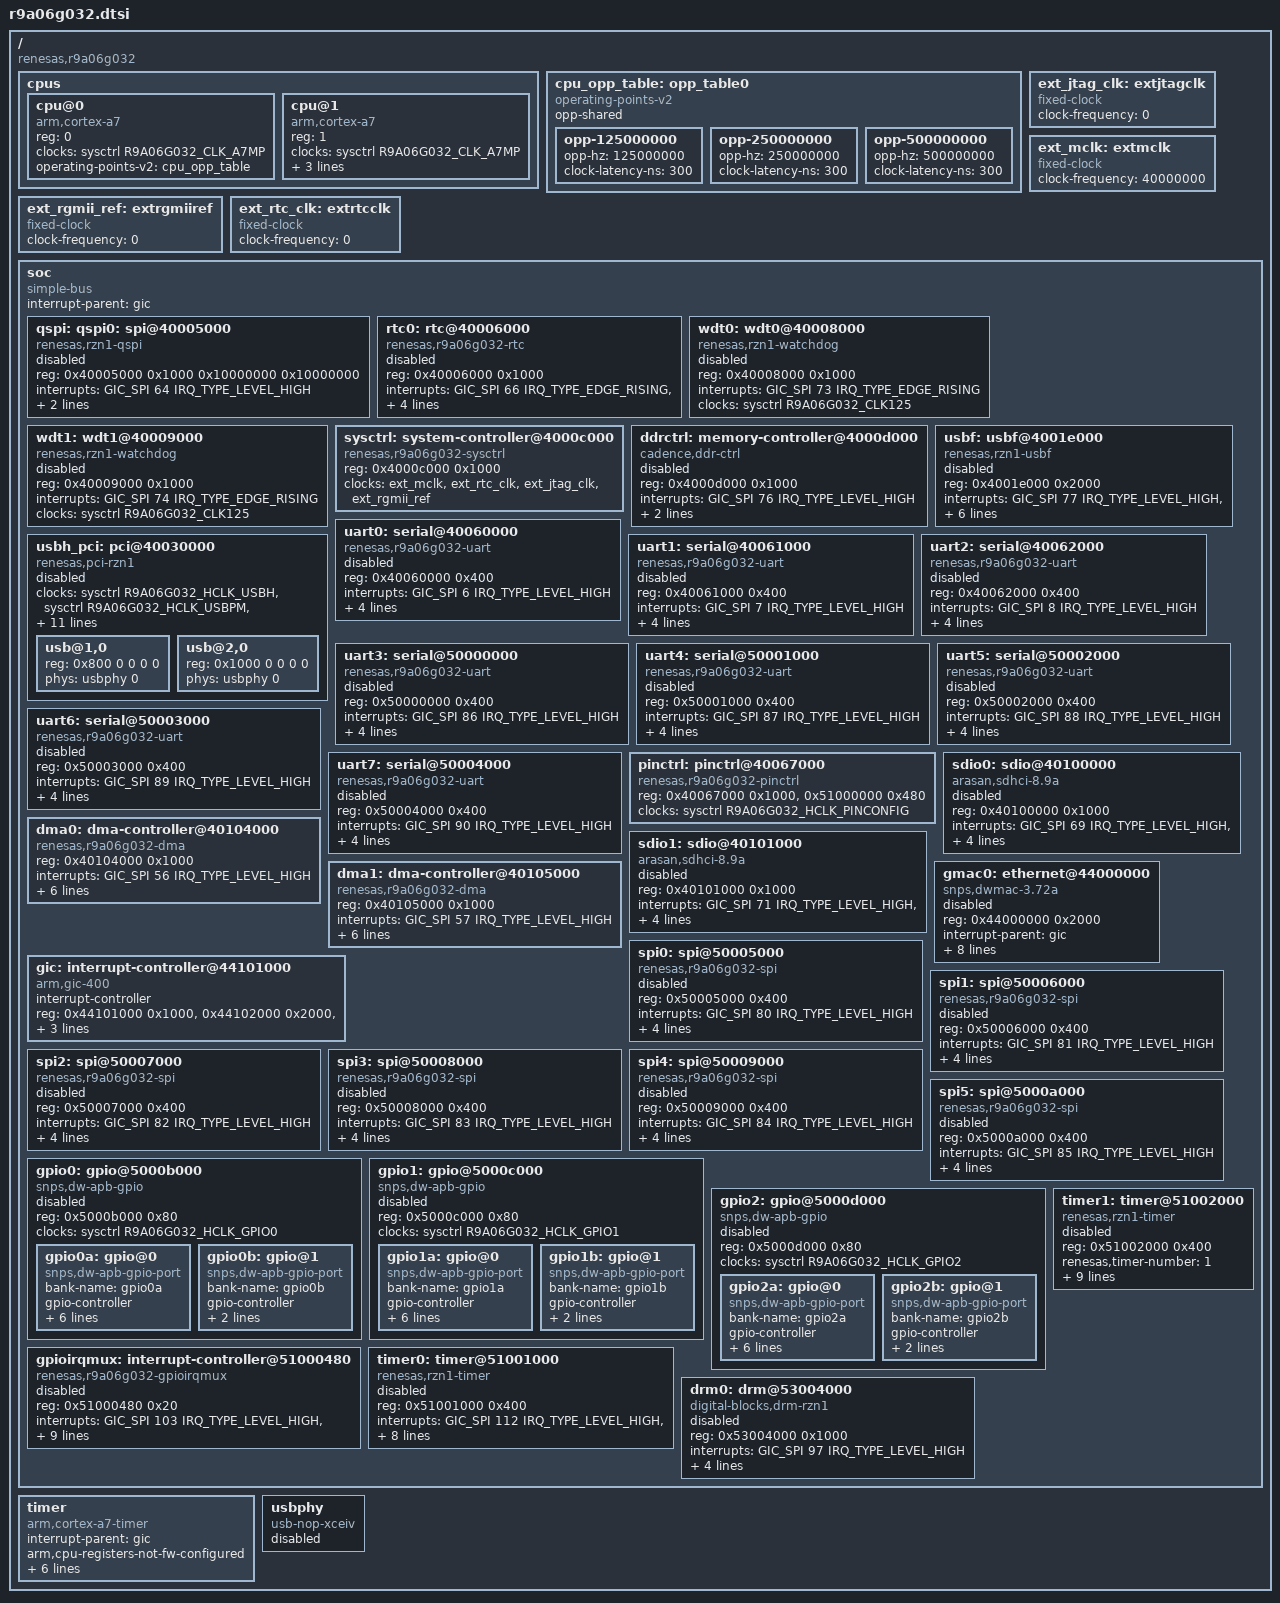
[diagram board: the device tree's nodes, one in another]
// SPDX-License-Identifier: GPL-2.0
/*
 * Base Device Tree Source for the Renesas RZ/N1D (R9A06G032)
 *
 * Copyright (C) 2018 Renesas Electronics Europe Limited
 *
 */

#include <dt-bindings/interrupt-controller/arm-gic.h>
#include <dt-bindings/clock/r9a06g032-sysctrl.h>
#include <dt-bindings/gpio/gpio.h>

/ {
	compatible = "renesas,r9a06g032";
	#address-cells = <1>;
	#size-cells = <1>;

	cpus {
		#address-cells = <1>;
		#size-cells = <0>;

		cpu@0 {
			device_type = "cpu";
			compatible = "arm,cortex-a7";
			reg = <0>;
			clocks = <&sysctrl R9A06G032_CLK_A7MP>;
			operating-points-v2 = <&cpu_opp_table>;
		};

		cpu@1 {
			device_type = "cpu";
			compatible = "arm,cortex-a7";
			reg = <1>;
			clocks = <&sysctrl R9A06G032_CLK_A7MP>;
			enable-method = "renesas,r9a06g032-smp";
			cpu-release-addr = <0 0x4000c204>;
			operating-points-v2 = <&cpu_opp_table>;
		};
	};

	cpu_opp_table: opp_table0 {
		compatible = "operating-points-v2";
		opp-shared;

		opp-125000000 {
			opp-hz = /bits/ 64 <125000000>;
			/* ~35 clocks cycles at 125mhz */
			clock-latency-ns = <300>;
		};
		opp-250000000 {
			opp-hz = /bits/ 64 <250000000>;
			clock-latency-ns = <300>;
		};
		opp-500000000 {
			opp-hz = /bits/ 64 <500000000>;
			clock-latency-ns = <300>;
		};
	};

	ext_jtag_clk: extjtagclk {
		#clock-cells = <0>;
		compatible = "fixed-clock";
		clock-frequency = <0>;
	};

	ext_mclk: extmclk {
		#clock-cells = <0>;
		compatible = "fixed-clock";
		clock-frequency = <40000000>;
	};

	ext_rgmii_ref: extrgmiiref {
		#clock-cells = <0>;
		compatible = "fixed-clock";
		clock-frequency = <0>;
	};

	ext_rtc_clk: extrtcclk {
		#clock-cells = <0>;
		compatible = "fixed-clock";
		clock-frequency = <0>;
	};

	soc {
		compatible = "simple-bus";
		#address-cells = <1>;
		#size-cells = <1>;
		interrupt-parent = <&gic>;
		ranges;

		qspi: qspi0: spi@40005000 {
			compatible = "renesas,rzn1-qspi";
			#address-cells = <1>;
			#size-cells = <0>;
			reg = <0x40005000 0x1000
			       0x10000000 0x10000000>;
			reg-names = "qspi", "qspi-mapping";
			interrupts = <GIC_SPI 64 IRQ_TYPE_LEVEL_HIGH>;
			clocks = <&sysctrl R9A06G032_HCLK_QSPI0>, <&sysctrl R9A06G032_CLK_QSPI0>;
			clock-names = "hclk", "pclk";
			status = "disabled";
		};

		rtc0: rtc@40006000 {
			compatible = "renesas,r9a06g032-rtc", "renesas,rzn1-rtc";
			reg = <0x40006000 0x1000>;
			interrupts = <GIC_SPI 66 IRQ_TYPE_EDGE_RISING>,
				     <GIC_SPI 67 IRQ_TYPE_EDGE_RISING>,
				     <GIC_SPI 68 IRQ_TYPE_EDGE_RISING>;
			interrupt-names = "alarm", "timer", "pps";
			clocks = <&sysctrl R9A06G032_HCLK_RTC>;
			clock-names = "hclk";
			power-domains = <&sysctrl>;
			status = "disabled";
		};

		wdt0: wdt0@40008000 {
			compatible = "renesas,rzn1-watchdog";
			reg = <0x40008000 0x1000>;
			interrupts = <GIC_SPI 73 IRQ_TYPE_EDGE_RISING>;
			clocks = <&sysctrl R9A06G032_CLK125>;
			status = "disabled";
		};

		wdt1: wdt1@40009000 {
			compatible = "renesas,rzn1-watchdog";
			reg = <0x40009000 0x1000>;
			interrupts = <GIC_SPI 74 IRQ_TYPE_EDGE_RISING>;
			clocks = <&sysctrl R9A06G032_CLK125>;
			status = "disabled";
		};

		sysctrl: system-controller@4000c000 {
			compatible = "renesas,r9a06g032-sysctrl";
			reg = <0x4000c000 0x1000>;
			status = "okay";
			#clock-cells = <1>;
			#power-domain-cells = <0>;

			clocks = <&ext_mclk>, <&ext_rtc_clk>,
					<&ext_jtag_clk>, <&ext_rgmii_ref>;
			clock-names = "mclk", "rtc", "jtag", "rgmii_ref_ext";
		};

		ddrctrl: memory-controller@4000d000 {
			compatible = "cadence,ddr-ctrl";
			reg = <0x4000d000 0x1000>;
			interrupts = <GIC_SPI 76 IRQ_TYPE_LEVEL_HIGH>;
			clocks = <&sysctrl R9A06G032_CLK_DDRC>, <&sysctrl R9A06G032_HCLK_DDRC>;
			status = "disabled";
		};

		usbf: usbf@4001e000 {
			compatible = "renesas,rzn1-usbf";
			reg = <0x4001e000 0x2000>;
			interrupts = <GIC_SPI 77 IRQ_TYPE_LEVEL_HIGH>,
				     <GIC_SPI 78 IRQ_TYPE_LEVEL_HIGH>;
			interrupt-names = "epc", "usbf";
			clocks = <&sysctrl R9A06G032_HCLK_USBF>,
				 <&sysctrl R9A06G032_HCLK_USBPM>;
			clock-names = "axi", "usbpm";
			renesas,sram-size = <5024>; /* 32 bits words */
			/* Allow 4 x 512 byte packets per endpoint to support MTU of 1500.
			 * Due to protocol overheads, 3 x 512 byte packets is not enough. */
			renesas,sram-conf,g_ether = <4 2 0>;
			renesas,sram-conf,g_mass_storage = <8 8 0 0 0 0>;
			status = "disabled";
		};

		usbh_pci: pci@40030000 {
			compatible = "renesas,pci-rzn1";
			device_type = "pci";
			clock-names = "axi";
			clocks = <&sysctrl R9A06G032_HCLK_USBH>,
				 <&sysctrl R9A06G032_HCLK_USBPM>,
				 <&sysctrl R9A06G032_CLK_PCI_USB>;
			reg = <0x40030000 0xc00>,
			      <0x40020000 0x1100>;
			interrupts = <GIC_SPI 79 IRQ_TYPE_LEVEL_HIGH>;
			status = "disabled";

			bus-range = <0 0>;
			#address-cells = <3>;
			#size-cells = <2>;
			#interrupt-cells = <1>;
			ranges = <0x02000000 0 0x40020000 0x40020000 0 0x00010000>;
			/* Should map all possible DDR as inbound ranges, but
			 * the IP only supports a 256MB, 512MB, or 1GB window.
			 * flags, PCI addr (64-bit), CPU addr, PCI size (64-bit)
			 */
			dma-ranges = <0x42000000 0 0x80000000 0x80000000 0 0x40000000>;
			interrupt-map-mask = <0xff00 0 0 0x7>;
			interrupt-map = <0x0000 0 0 1 &gic GIC_SPI 79 IRQ_TYPE_LEVEL_HIGH
					 0x0800 0 0 1 &gic GIC_SPI 79 IRQ_TYPE_LEVEL_HIGH
					 0x1000 0 0 2 &gic GIC_SPI 79 IRQ_TYPE_LEVEL_HIGH>;

			usb@1,0 {
				reg = <0x800 0 0 0 0>;
				phys = <&usbphy 0>;
				phy-names = "usb";
			};

			usb@2,0 {
				reg = <0x1000 0 0 0 0>;
				phys = <&usbphy 0>;
				phy-names = "usb";
			};
		};

		uart0: serial@40060000 {
			compatible = "renesas,r9a06g032-uart", "renesas,rzn1-uart", "snps,dw-apb-uart";
			reg = <0x40060000 0x400>;
			interrupts = <GIC_SPI 6 IRQ_TYPE_LEVEL_HIGH>;
			reg-shift = <2>;
			reg-io-width = <4>;
			clocks = <&sysctrl R9A06G032_CLK_UART0>, <&sysctrl R9A06G032_HCLK_UART0>;
			clock-names = "baudclk", "apb_pclk";
			status = "disabled";
		};

		uart1: serial@40061000 {
			compatible = "renesas,r9a06g032-uart", "renesas,rzn1-uart", "snps,dw-apb-uart";
			reg = <0x40061000 0x400>;
			interrupts = <GIC_SPI 7 IRQ_TYPE_LEVEL_HIGH>;
			reg-shift = <2>;
			reg-io-width = <4>;
			clocks = <&sysctrl R9A06G032_CLK_UART1>, <&sysctrl R9A06G032_HCLK_UART1>;
			clock-names = "baudclk", "apb_pclk";
			status = "disabled";
		};

		uart2: serial@40062000 {
			compatible = "renesas,r9a06g032-uart", "renesas,rzn1-uart", "snps,dw-apb-uart";
			reg = <0x40062000 0x400>;
			interrupts = <GIC_SPI 8 IRQ_TYPE_LEVEL_HIGH>;
			reg-shift = <2>;
			reg-io-width = <4>;
			clocks = <&sysctrl R9A06G032_CLK_UART2>, <&sysctrl R9A06G032_HCLK_UART2>;
			clock-names = "baudclk", "apb_pclk";
			status = "disabled";
		};

		uart3: serial@50000000 {
			compatible = "renesas,r9a06g032-uart", "renesas,rzn1-uart";
			reg = <0x50000000 0x400>;
			interrupts = <GIC_SPI 86 IRQ_TYPE_LEVEL_HIGH>;
			reg-shift = <2>;
			reg-io-width = <4>;
			clocks = <&sysctrl R9A06G032_CLK_UART3>, <&sysctrl R9A06G032_HCLK_UART3>;
			clock-names = "baudclk", "apb_pclk";
			status = "disabled";
		};

		uart4: serial@50001000 {
			compatible = "renesas,r9a06g032-uart", "renesas,rzn1-uart";
			reg = <0x50001000 0x400>;
			interrupts = <GIC_SPI 87 IRQ_TYPE_LEVEL_HIGH>;
			reg-shift = <2>;
			reg-io-width = <4>;
			clocks = <&sysctrl R9A06G032_CLK_UART4>, <&sysctrl R9A06G032_HCLK_UART4>;
			clock-names = "baudclk", "apb_pclk";
			status = "disabled";
		};

		uart5: serial@50002000 {
			compatible = "renesas,r9a06g032-uart", "renesas,rzn1-uart";
			reg = <0x50002000 0x400>;
			interrupts = <GIC_SPI 88 IRQ_TYPE_LEVEL_HIGH>;
			reg-shift = <2>;
			reg-io-width = <4>;
			clocks = <&sysctrl R9A06G032_CLK_UART5>, <&sysctrl R9A06G032_HCLK_UART5>;
			clock-names = "baudclk", "apb_pclk";
			status = "disabled";
		};

		uart6: serial@50003000 {
			compatible = "renesas,r9a06g032-uart", "renesas,rzn1-uart";
			reg = <0x50003000 0x400>;
			interrupts = <GIC_SPI 89 IRQ_TYPE_LEVEL_HIGH>;
			reg-shift = <2>;
			reg-io-width = <4>;
			clocks = <&sysctrl R9A06G032_CLK_UART6>, <&sysctrl R9A06G032_HCLK_UART6>;
			clock-names = "baudclk", "apb_pclk";
			status = "disabled";
		};

		uart7: serial@50004000 {
			compatible = "renesas,r9a06g032-uart", "renesas,rzn1-uart";
			reg = <0x50004000 0x400>;
			interrupts = <GIC_SPI 90 IRQ_TYPE_LEVEL_HIGH>;
			reg-shift = <2>;
			reg-io-width = <4>;
			clocks = <&sysctrl R9A06G032_CLK_UART7>, <&sysctrl R9A06G032_HCLK_UART7>;
			clock-names = "baudclk", "apb_pclk";
			status = "disabled";
		};

		pinctrl: pinctrl@40067000 {
			compatible = "renesas,r9a06g032-pinctrl", "renesas,rzn1-pinctrl";
			reg = <0x40067000 0x1000>, <0x51000000 0x480>;
			clocks = <&sysctrl R9A06G032_HCLK_PINCONFIG>;
			clock-names = "bus";
			status = "okay";
		};

		sdio0: sdio@40100000 {
			compatible = "arasan,sdhci-8.9a";
			reg = <0x40100000 0x1000>;
			interrupts = <GIC_SPI 69 IRQ_TYPE_LEVEL_HIGH>,
				     <GIC_SPI 70 IRQ_TYPE_LEVEL_HIGH>;
			clocks = <&sysctrl R9A06G032_CLK_SDIO0>, <&sysctrl R9A06G032_HCLK_SDIO0>;
			clock-names = "clk_xin", "clk_ahb";
			no-1-8-v;
			status = "disabled";
		};

		sdio1: sdio@40101000 {
			compatible = "arasan,sdhci-8.9a";
			reg = <0x40101000 0x1000>;
			interrupts = <GIC_SPI 71 IRQ_TYPE_LEVEL_HIGH>,
				     <GIC_SPI 72 IRQ_TYPE_LEVEL_HIGH>;
			clocks = <&sysctrl R9A06G032_CLK_SDIO1>, <&sysctrl R9A06G032_HCLK_SDIO1>;
			clock-names = "clk_xin", "clk_ahb";
			no-1-8-v;
			status = "disabled";
		};

		dma0: dma-controller@40104000 {
			compatible = "renesas,r9a06g032-dma", "renesas,rzn1-dma";
			reg = <0x40104000 0x1000>;
			interrupts = <GIC_SPI 56 IRQ_TYPE_LEVEL_HIGH>;
			clock-names = "hclk";
			clocks = <&sysctrl R9A06G032_HCLK_DMA0>;
			dma-channels = <8>;
			dma-requests = <16>;
			dma-masters = <1>;
			#dma-cells = <3>;
			block_size = <0xfff>;
			data-width = <8>;
		};

		dma1: dma-controller@40105000 {
			compatible = "renesas,r9a06g032-dma", "renesas,rzn1-dma";
			reg = <0x40105000 0x1000>;
			interrupts = <GIC_SPI 57 IRQ_TYPE_LEVEL_HIGH>;
			clock-names = "hclk";
			clocks = <&sysctrl R9A06G032_HCLK_DMA1>;
			dma-channels = <8>;
			dma-requests = <16>;
			dma-masters = <1>;
			#dma-cells = <3>;
			block_size = <0xfff>;
			data-width = <8>;
		};

		gmac0: ethernet@44000000 {
			compatible = "snps,dwmac-3.72a", "snps,dwmac";
			reg = <0x44000000 0x2000>;
			interrupt-parent = <&gic>;
			interrupts = <GIC_SPI 34 IRQ_TYPE_LEVEL_HIGH>,
				     <GIC_SPI 35 IRQ_TYPE_LEVEL_HIGH>,
				     <GIC_SPI 36 IRQ_TYPE_LEVEL_HIGH>;
			interrupt-names = "macirq", "eth_lpi", "eth_wake_irq";
			clock-names = "stmmaceth";
			clocks = <&sysctrl R9A06G032_HCLK_GMAC0>;
			snps,multicast-filter-bins = <256>;
			snps,perfect-filter-entries = <128>;
			tx-fifo-depth = <2048>;
			rx-fifo-depth = <4096>;
			status = "disabled";
		};

		gic: interrupt-controller@44101000 {
			compatible = "arm,gic-400", "arm,cortex-a7-gic";
			interrupt-controller;
			#interrupt-cells = <3>;
			reg = <0x44101000 0x1000>, /* Distributer */
			      <0x44102000 0x2000>, /* CPU interface */
			      <0x44104000 0x2000>, /* Virt interface control */
			      <0x44106000 0x2000>; /* Virt CPU interface */
			interrupts =
				<GIC_PPI 9 (GIC_CPU_MASK_SIMPLE(2) | IRQ_TYPE_LEVEL_HIGH)>;
		};

		/*
		 * SPI 0-3 are Master; 4-5 are Slave. 4-16 bits data width
		 * dw_apb-ssi is configured with 16*16 bits FIFO in both
		 * directions.
		 * 4 Chipselects for the master interfaces, 1 for slaves
		 */
		spi0: spi@50005000 {
			compatible = "renesas,r9a06g032-spi", "renesas,rzn1-spi";
			reg = <0x50005000 0x400>;
			interrupts = <GIC_SPI 80 IRQ_TYPE_LEVEL_HIGH>;
			clocks = <&sysctrl R9A06G032_CLK_SPI0>, <&sysctrl R9A06G032_HCLK_SPI0>;
			clock-names = "ssi_clk", "pclk";
			#address-cells = <1>;
			#size-cells = <0>;
			spi-max-frequency = <12500000>;
			num-cs = <4>;
			status = "disabled";
		};

		spi1: spi@50006000 {
			compatible = "renesas,r9a06g032-spi", "renesas,rzn1-spi";
			reg = <0x50006000 0x400>;
			interrupts = <GIC_SPI 81 IRQ_TYPE_LEVEL_HIGH>;
			clocks = <&sysctrl R9A06G032_CLK_SPI1>, <&sysctrl R9A06G032_HCLK_SPI1>;
			clock-names = "ssi_clk", "pclk";
			#address-cells = <1>;
			#size-cells = <0>;
			spi-max-frequency = <12500000>;
			num-cs = <4>;
			status = "disabled";
		};

		spi2: spi@50007000 {
			compatible = "renesas,r9a06g032-spi", "renesas,rzn1-spi";
			reg = <0x50007000 0x400>;
			interrupts = <GIC_SPI 82 IRQ_TYPE_LEVEL_HIGH>;
			clocks = <&sysctrl R9A06G032_CLK_SPI2>, <&sysctrl R9A06G032_HCLK_SPI2>;
			clock-names = "ssi_clk", "pclk";
			#address-cells = <1>;
			#size-cells = <0>;
			spi-max-frequency = <12500000>;
			num-cs = <4>;
			status = "disabled";
		};

		spi3: spi@50008000 {
			compatible = "renesas,r9a06g032-spi", "renesas,rzn1-spi";
			reg = <0x50008000 0x400>;
			interrupts = <GIC_SPI 83 IRQ_TYPE_LEVEL_HIGH>;
			clocks = <&sysctrl R9A06G032_CLK_SPI3>, <&sysctrl R9A06G032_HCLK_SPI3>;
			clock-names = "ssi_clk", "pclk";
			#address-cells = <1>;
			#size-cells = <0>;
			spi-max-frequency = <12500000>;
			num-cs = <4>;
			status = "disabled";
		};

		spi4: spi@50009000 {
			compatible = "renesas,r9a06g032-spi", "renesas,rzn1-spi";
			reg = <0x50009000 0x400>;
			interrupts = <GIC_SPI 84 IRQ_TYPE_LEVEL_HIGH>;
			clocks = <&sysctrl R9A06G032_CLK_SPI4>, <&sysctrl R9A06G032_HCLK_SPI4>;
			clock-names = "ssi_clk", "pclk";
			#address-cells = <1>;
			#size-cells = <0>;
			spi-max-frequency = <12500000>;
			num-cs = <1>; /* Slave interface */
			status = "disabled";
		};

		spi5: spi@5000a000 {
			compatible = "renesas,r9a06g032-spi", "renesas,rzn1-spi";
			reg = <0x5000a000 0x400>;
			interrupts = <GIC_SPI 85 IRQ_TYPE_LEVEL_HIGH>;
			clocks = <&sysctrl R9A06G032_CLK_SPI5>, <&sysctrl R9A06G032_HCLK_SPI5>;
			clock-names = "ssi_clk", "pclk";
			#address-cells = <1>;
			#size-cells = <0>;
			spi-max-frequency = <12500000>;
			num-cs = <1>; /* Slave interface */
			status = "disabled";
		};

		/*
		 * The GPIO mapping to the corresponding pins is complicated,
		 * see the hardware documentation for details.
		 */
		gpio0: gpio@5000b000 {
			compatible = "snps,dw-apb-gpio";
			reg = <0x5000b000 0x80>;
			#address-cells = <1>;
			#size-cells = <0>;
			clocks = <&sysctrl R9A06G032_HCLK_GPIO0>;
			clock-names = "bus";
			status = "disabled";

			/* GPIO0a[0]      corresponds to pin  0      */
			/* GPIO0a[1..2]   corresponds to pins 3..4   */
			/* GPIO0a[3..4]   corresponds to pins 9..10  */
			/* GPIO0a[5]      corresponds to pin  12     */
			/* GPIO0a[6..7]   corresponds to pins 15..16 */
			/* GPIO0a[8..9]   corresponds to pins 21..22 */
			/* GPIO0a[10]     corresponds to pin  24     */
			/* GPIO0a[11..12] corresponds to pins 27..28 */
			/* GPIO0a[13..14] corresponds to pins 33..34 */
			/* GPIO0a[15]     corresponds to pin  36     */
			/* GPIO0a[16..17] corresponds to pins 39..40 */
			/* GPIO0a[18..19] corresponds to pins 45..46 */
			/* GPIO0a[20]     corresponds to pin  48     */
			/* GPIO0a[21..22] corresponds to pins 51..52 */
			/* GPIO0a[23..24] corresponds to pins 57..58 */
			/* GPIO0a[25..31] corresponds to pins 62..68 */
			gpio0a: gpio@0 {
				compatible = "snps,dw-apb-gpio-port";
				bank-name = "gpio0a";
				gpio-controller;
				#gpio-cells = <2>;
				snps,nr-gpios = <32>;
				reg = <0>;

				interrupt-controller;
				interrupt-parent = <&gpioirqmux>;
				interrupts =   < 0  1  2  3  4  5  6  7
						 8  9 10 11 12 13 14 15
						16 17 18 19 20 21 22 23
						24 25 26 27 28 29 30 31 >;
				#interrupt-cells = <2>;
			};

			/* GPIO0b[0..1]   corresponds to pins 1..2   */
			/* GPIO0b[2..5]   corresponds to pins 5..8   */
			/* GPIO0b[6]      corresponds to pin  11     */
			/* GPIO0b[7..8]   corresponds to pins 13..14 */
			/* GPIO0b[9..12]  corresponds to pins 17..20 */
			/* GPIO0b[13]     corresponds to pin  23     */
			/* GPIO0b[14..15] corresponds to pins 25..26 */
			/* GPIO0b[16..19] corresponds to pins 29..32 */
			/* GPIO0b[20]     corresponds to pin  35     */
			/* GPIO0b[21..22] corresponds to pins 37..38 */
			/* GPIO0b[23..26] corresponds to pins 41..44 */
			/* GPIO0b[27]     corresponds to pin  47     */
			/* GPIO0b[28..29] corresponds to pins 49..50 */
			/* GPIO0b[30..31] corresponds to pins 53..54 */
			gpio0b: gpio@1 {
				compatible = "snps,dw-apb-gpio-port";
				bank-name = "gpio0b";
				gpio-controller;
				#gpio-cells = <2>;
				snps,nr-gpios = <32>;
				reg = <1>;
			};
		};

		gpio1: gpio@5000c000 {
			compatible = "snps,dw-apb-gpio";
			reg = <0x5000c000 0x80>;
			#address-cells = <1>;
			#size-cells = <0>;
			clocks = <&sysctrl R9A06G032_HCLK_GPIO1>;
			clock-names = "bus";
			status = "disabled";

			/* GPIO1a[0..4] corresponds to pins 69..73 */
			/* GPIO1a[5..31] corresponds to pins 95..121 */
			gpio1a: gpio@0 {
				compatible = "snps,dw-apb-gpio-port";
				bank-name = "gpio1a";
				gpio-controller;
				#gpio-cells = <2>;
				snps,nr-gpios = <32>;
				reg = <0>;

				interrupt-controller;
				interrupt-parent = <&gpioirqmux>;
				interrupts =  < 32 33 34 35 36 37 38 39
						40 41 42 43 44 45 46 47
						48 49 50 51 52 53 54 55
						56 57 58 59 60 61 62 63 >;
				#interrupt-cells = <2>;
			};

			/* GPIO1b[0..1] corresponds to pins 55..56 */
			/* GPIO1b[2..4] corresponds to pins 59..61 */
			/* GPIO1b[5..25] corresponds to pins 74..94 */
			/* GPIO1b[26..31] corresponds to pins 150..155 */
			gpio1b: gpio@1 {
				compatible = "snps,dw-apb-gpio-port";
				bank-name = "gpio1b";
				gpio-controller;
				#gpio-cells = <2>;
				snps,nr-gpios = <32>;
				reg = <1>;
			};
		};

		gpio2: gpio@5000d000 {
			compatible = "snps,dw-apb-gpio";
			reg = <0x5000d000 0x80>;
			#address-cells = <1>;
			#size-cells = <0>;
			clocks = <&sysctrl R9A06G032_HCLK_GPIO2>;
			clock-names = "bus";
			status = "disabled";

			/* GPIO2a[0..27] corresponds to pins 122..149 */
			/* GPIO2a[28..31] corresponds to pins 156..159 */
			gpio2a: gpio@0 {
				compatible = "snps,dw-apb-gpio-port";
				bank-name = "gpio2a";
				gpio-controller;
				#gpio-cells = <2>;
				snps,nr-gpios = <32>;
				reg = <0>;

				interrupt-controller;
				interrupt-parent = <&gpioirqmux>;
				interrupts =  < 64 65 66 67 68 69 70 71
						72 73 74 75 76 77 78 79
						80 81 82 83 84 85 86 87
						88 89 90 91 92 93 94 95 >;
				#interrupt-cells = <2>;
			};

			/* GPIO2b[0..9] corresponds to pins 160..169 */
			gpio2b: gpio@1 {
				compatible = "snps,dw-apb-gpio-port";
				bank-name = "gpio2b";
				gpio-controller;
				#gpio-cells = <2>;
				snps,nr-gpios = <10>;
				reg = <1>;
			};
		};

		gpioirqmux: interrupt-controller@51000480 {
			compatible = "renesas,r9a06g032-gpioirqmux",
				     "renesas,rzn1-gpioirqmux";
			reg = <0x51000480 0x20>;
			interrupts = <GIC_SPI 103 IRQ_TYPE_LEVEL_HIGH>,
				     <GIC_SPI 104 IRQ_TYPE_LEVEL_HIGH>,
				     <GIC_SPI 105 IRQ_TYPE_LEVEL_HIGH>,
				     <GIC_SPI 106 IRQ_TYPE_LEVEL_HIGH>,
				     <GIC_SPI 107 IRQ_TYPE_LEVEL_HIGH>,
				     <GIC_SPI 108 IRQ_TYPE_LEVEL_HIGH>,
				     <GIC_SPI 109 IRQ_TYPE_LEVEL_HIGH>,
				     <GIC_SPI 110 IRQ_TYPE_LEVEL_HIGH>;
			#interrupt-cells = <1>;
			#address-cells = <0>;
			interrupt-controller;
			interrupt-map-mask = <0x3f>;
			status = "disabled";
		};

		timer0: timer@51001000 {
			compatible = "renesas,rzn1-timer";
			reg = <0x51001000 0x400>;
			interrupts = <GIC_SPI 112 IRQ_TYPE_LEVEL_HIGH>,
				     <GIC_SPI 113 IRQ_TYPE_LEVEL_HIGH>,
				     <GIC_SPI 114 IRQ_TYPE_LEVEL_HIGH>,
				     <GIC_SPI 115 IRQ_TYPE_LEVEL_HIGH>,
				     <GIC_SPI 116 IRQ_TYPE_LEVEL_HIGH>,
				     <GIC_SPI 117 IRQ_TYPE_LEVEL_HIGH>,
				     <GIC_SPI 118 IRQ_TYPE_LEVEL_HIGH>,
				     <GIC_SPI 119 IRQ_TYPE_LEVEL_HIGH>;
			clocks = <&sysctrl R9A06G032_HCLK_TIMER0>;
			status = "disabled";
		};

		timer1: timer@51002000 {
			compatible = "renesas,rzn1-timer";
			reg = <0x51002000 0x400>;
			renesas,timer-number = <1>;
			interrupts = <GIC_SPI 120 IRQ_TYPE_LEVEL_HIGH>,
				     <GIC_SPI 121 IRQ_TYPE_LEVEL_HIGH>,
				     <GIC_SPI 122 IRQ_TYPE_LEVEL_HIGH>,
				     <GIC_SPI 123 IRQ_TYPE_LEVEL_HIGH>,
				     <GIC_SPI 124 IRQ_TYPE_LEVEL_HIGH>,
				     <GIC_SPI 125 IRQ_TYPE_LEVEL_HIGH>,
				     <GIC_SPI 126 IRQ_TYPE_LEVEL_HIGH>,
				     <GIC_SPI 127 IRQ_TYPE_LEVEL_HIGH>;
			clocks = <&sysctrl R9A06G032_HCLK_TIMER1>;
			status = "disabled";
		};

		drm0: drm@53004000 {
			compatible = "digital-blocks,drm-rzn1";
			reg = <0x53004000 0x1000>;
			interrupts = <GIC_SPI 97 IRQ_TYPE_LEVEL_HIGH>;
			clocks = <&sysctrl R9A06G032_CLK_SLCD>,
				 <&sysctrl R9A06G032_HCLK_LCD>,
				 <&sysctrl R9A06G032_HCLK_PG_I>;
			clock-names = "lcd_eclk", "ahb", "lcd_pclk";
			status = "disabled";
			power-domains = <&sysctrl>;
			#pwm-cells = <2>;
		};
	};

	timer {
		compatible = "arm,cortex-a7-timer",
			     "arm,armv7-timer";
		interrupt-parent = <&gic>;
		arm,cpu-registers-not-fw-configured;
		always-on;
		interrupts =
			<GIC_PPI 13 (GIC_CPU_MASK_SIMPLE(2) | IRQ_TYPE_LEVEL_LOW)>,
			<GIC_PPI 14 (GIC_CPU_MASK_SIMPLE(2) | IRQ_TYPE_LEVEL_LOW)>,
			<GIC_PPI 11 (GIC_CPU_MASK_SIMPLE(2) | IRQ_TYPE_LEVEL_LOW)>,
			<GIC_PPI 10 (GIC_CPU_MASK_SIMPLE(2) | IRQ_TYPE_LEVEL_LOW)>;
	};

	usbphy: usbphy {
		#phy-cells = <0>;
		compatible = "usb-nop-xceiv";
		status = "disabled";
	};
};
